# N572F065_v3 register map
File version: 1.0
Registers are 32-bit, read-write, reset 0x0 unless marked. A register's access mark holds for its fields unless they carry their own. Offsets are from the block's base; [hi:lo] are bit positions; 'fields as' and 'values as' point back to an identical list.

## CLK — CLK Register Map
Base 0x50000200
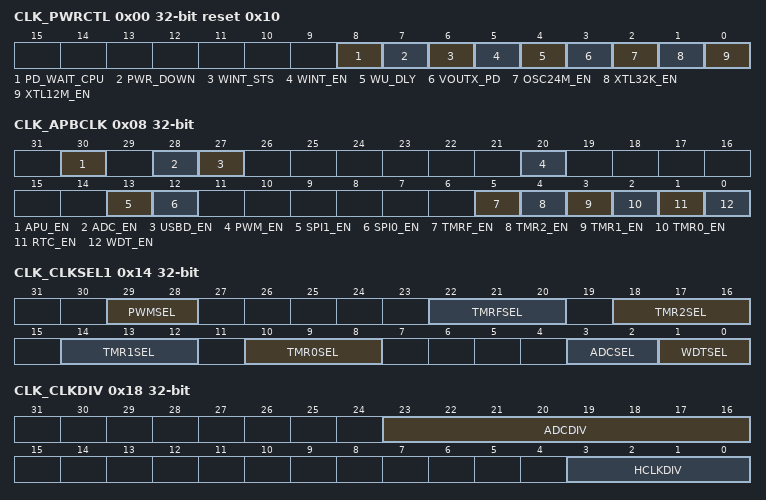
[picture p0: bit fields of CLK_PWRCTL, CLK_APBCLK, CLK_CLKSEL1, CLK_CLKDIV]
0x00 CLK_PWRCTL reset 0x10 (reset mask 0xFFFFFFF0) — System Power Control Register
  [8] PD_WAIT_CPU — This Bit Controls The Power Down Entry Condition. Please refer to PWR_DOWN bit for the usage of PD_WAIT_CPU bit. The following is a brief description of PD_WAIT_CPU bit.
    0=Chip is at normal mode. Note that PWR_DOWN cannot be set to 1 when PD_WAIT_CPU value remains at 0, otherwise the chip may not wake up normally; 1=Chip waits to enter power-down mode
  [7] PWR_DOWN — System Power Down Active Or Enable Bit
    0=Chip operates at normal mode; 1=Chip is standing by power-down entry condition
  [6] WINT_STS — Chip Power Down Wake Up Status Flag. Set by "power down wake up", it indicates that resume from power down mode. The flag is set if the GPIO, USB, WDT or RTC wakeup. Note: Write 1 to clear the bit.
  [5] WINT_EN — Enable Interrupt When Wake Up From Power Down Mode
    0=Disable,; 1=Enable. The interrupt will occur when MCU wakes up from power down mode
  [4] WU_DLY — Enable The Wake Up Delay Counter. When the chip wakes up from idle mode, the clock control will delay some clock cycles to wait the 12MHz (or 6MHz) crystal or the internal 24MHz oscillator clock stable.
    0=Disable the clock cycles delay; 1=Enable the clock cycles delay. The delay is 4096 clock cycles for 12MHz (or 6MHz) crystal, 256 clock cycles for 24MHz oscillator
  [3] VOUTX_PD — Driving Out 3.0V (Through VOUTX Pad) LDO Control
    0=3.0V LDO (VOUTX) is enabled; 1=3.0V LDO (VOUTX) is disabled
  [2] OSC24M_EN — Internal 24MHz Oscillator Control. After reset, this bit is "1".
    0=24MHz oscillation is disabled; 1=24MHz Oscillation is enabled
  [1] XTL32K_EN — External 32.768KHz Crystal Control. After reset, this bit is "0".
    0=32.768KHz Crystal is disabled; 1=32.768KHz Crystal is enabled
  [0] XTL12M_EN — External 12MHz (or 6MHz) Crystal Oscillator Control. This bit is set by the combination logic of flash controller user configuration register CONFIG[26:24] after power on.
    0=12MHz (or 6MHz) crystal oscillation is disabled; 1=12MHz (or 6MHz) crystal oscillation is enabled
0x04 CLK_AHBCLK reset 0x4 — AHB Device Clock Enable Control Register
  [2] ISPCKEN — Flash ISP Engine Clock Enable Control
    0=To disable the Flash ISP engine clock; 1=To enable the Flash ISP engine clock
0x08 CLK_APBCLK (reset mask 0xFFFFFFF0) — APB Device Clock Enable Control Register
  [30] APU_EN — APU Clock Enable Control
    0=To disable the APU engine clock; 1=To enable the APU engine clock
  [28] ADC_EN — Audio Analog-Digital-Converter (ADC) Clock Enable Control
    0=Disable; 1=Enable
  [27] USBD_EN — USB FS Device Controller Clock Enable Control
    0=Disable; 1=Enable
  [20] PWM_EN — PWM Block Clock Enable Control
    0=Disable; 1=Enable
  [13] SPI1_EN — SPI1 Clock Enable Control
    0=Disable; 1=Enable
  [12] SPI0_EN — SPI0 Clock Enable Control
    0=Disable; 1=Enable
  [5] TMRF_EN — TimerF Clock Enable Control
    0=Disable; 1=Enable
  [4] TMR2_EN — Timer2 Clock Enable Control
    0=Disable; 1=Enable
  [3] TMR1_EN — Timer1 Clock Enable Control
    0=Disable; 1=Enable
  [2] TMR0_EN — Timer0 Clock Enable Control
    0=Disable; 1=Enable
  [1] RTC_EN — Real-Time-Clock APB Interface Clock Control. This bit is used to control the RTC APB clock only. The RTC engine clock source is from the 32.768KHz crystal.
    0=Disable; 1=Enable
  [0] WDT_EN — Watchdog Clock Enable Control. This bit is the protected bit. To program this bit needs an open lock sequence, write "59h", "16h", "88h" to register SYS_REGLCTL to un-lock this bit. Refer to the register SYS_REGLCTL at address SYS_BA+0x100. The default bit value is set according to the Flash Controller User Configuration Register CONFIG[31].
    0=Disable; 1=Enable
0x10 CLK_CLKSEL0 (reset mask 0xFFFFFFF0) — Clock Source Select Control Register 0
  [2:0] HCLKSEL — HCLK clock source select. Note: 1. Before clock switch, the related clock sources (pre-select and new-select) must be turned on. 2. The 3-bit default value is reloaded with the value of CFOSC (CONFIG[26:24]) in user configuration register in Flash controller by any reset. Therefore the default value is either 001b or 111b. Besides, before chip enters power down mode, HCLKSEL only can be either 001b or 111b.
    0=clock source from external 32KHz crystal clock; 1=clock source from external 12MHz (or 6MHz) crystal clock; 2=clock source from PLL1 output; 4=clock source from PLL2 output; 7=clock source from internal 24MHz oscillator clock
0x14 CLK_CLKSEL1 — Clock Source Select Control Register 1
  [29:28] PWMSEL — PWM Timer Clock Source Select
    0=Clock source from HCLK; 1=Clock source from external 32KHz crystal clock; 2=Clock source from external 12MHz (or 6MHz) crystal clock; 3=Clock source from internal 24MHz oscillator clock
  [22:20] TMRFSEL — TimerF Clock Source Select
    0=Clock source from external 32KHz crystal clock / 32; 1=Clock source from external 32KHz crystal clock / (4x32); 2=Clock source from external 12MHz (or 6MHz) crystal clock / 16384; 3=Clock source from external 12MHz (or 6MHz) crystal clock / (4x16384); 6=Clock source from 24MHz OSC clock / 32768; 7=Clock source from 24MHz OSC clock / (4x32768)
  [18:16] TMR2SEL — Timer2 Clock Source Select
    0=Clock source from HCLK; 1=Clock source from external 32KHz crystal clock. Clock source from internal 24MHz oscillator clock; 2=Clock source from external 12MHz (or 6MHz) crystal clock; 3=Clock source from external trigger
  [14:12] TMR1SEL — Timer1 Clock Source Select
    values as TMR2SEL
  [10:8] TMR0SEL — Timer0 Clock Source Select
    values as TMR2SEL
  [3:2] ADCSEL — ADC Clock Source Select
    0=Clock source from PLL2 clock; 1=Clock source from external 12MHz (or 6MHz) crystal clock. Clock source from internal 24MHz oscillator clock
  [1:0] WDTSEL — Watchdog Timer Clock Source Selection (Write Protect). These bits are protected bits. To program these bits needs an open lock sequence, write "59h", "16h", "88h" to SYS_REGLCTL to un-lock these bits. Refer to the register SYS_REGLCTL at address SYS_BA+0x100..
    0=Clock source from HCLK/2048 clock; 1=Clock source from external 32KHz crystal clock; 2=Clock source from external 12MHz (or 6MHz) crystal clock; 3=Clock source from internal 24MHz oscillator clock
0x18 CLK_CLKDIV — Clock Divider Number Register
  [23:16] ADCDIV — ADC Clock Divide Number From ADC Clock Source. The ADC clock must meet the constraint: ADCLK ( HCKL/2
  [3:0] HCLKDIV — HCLK Clock Divide Number From HCLK Clock Source
0x20 CLK_PLLCON reset 0x7 — PLL Control Register
